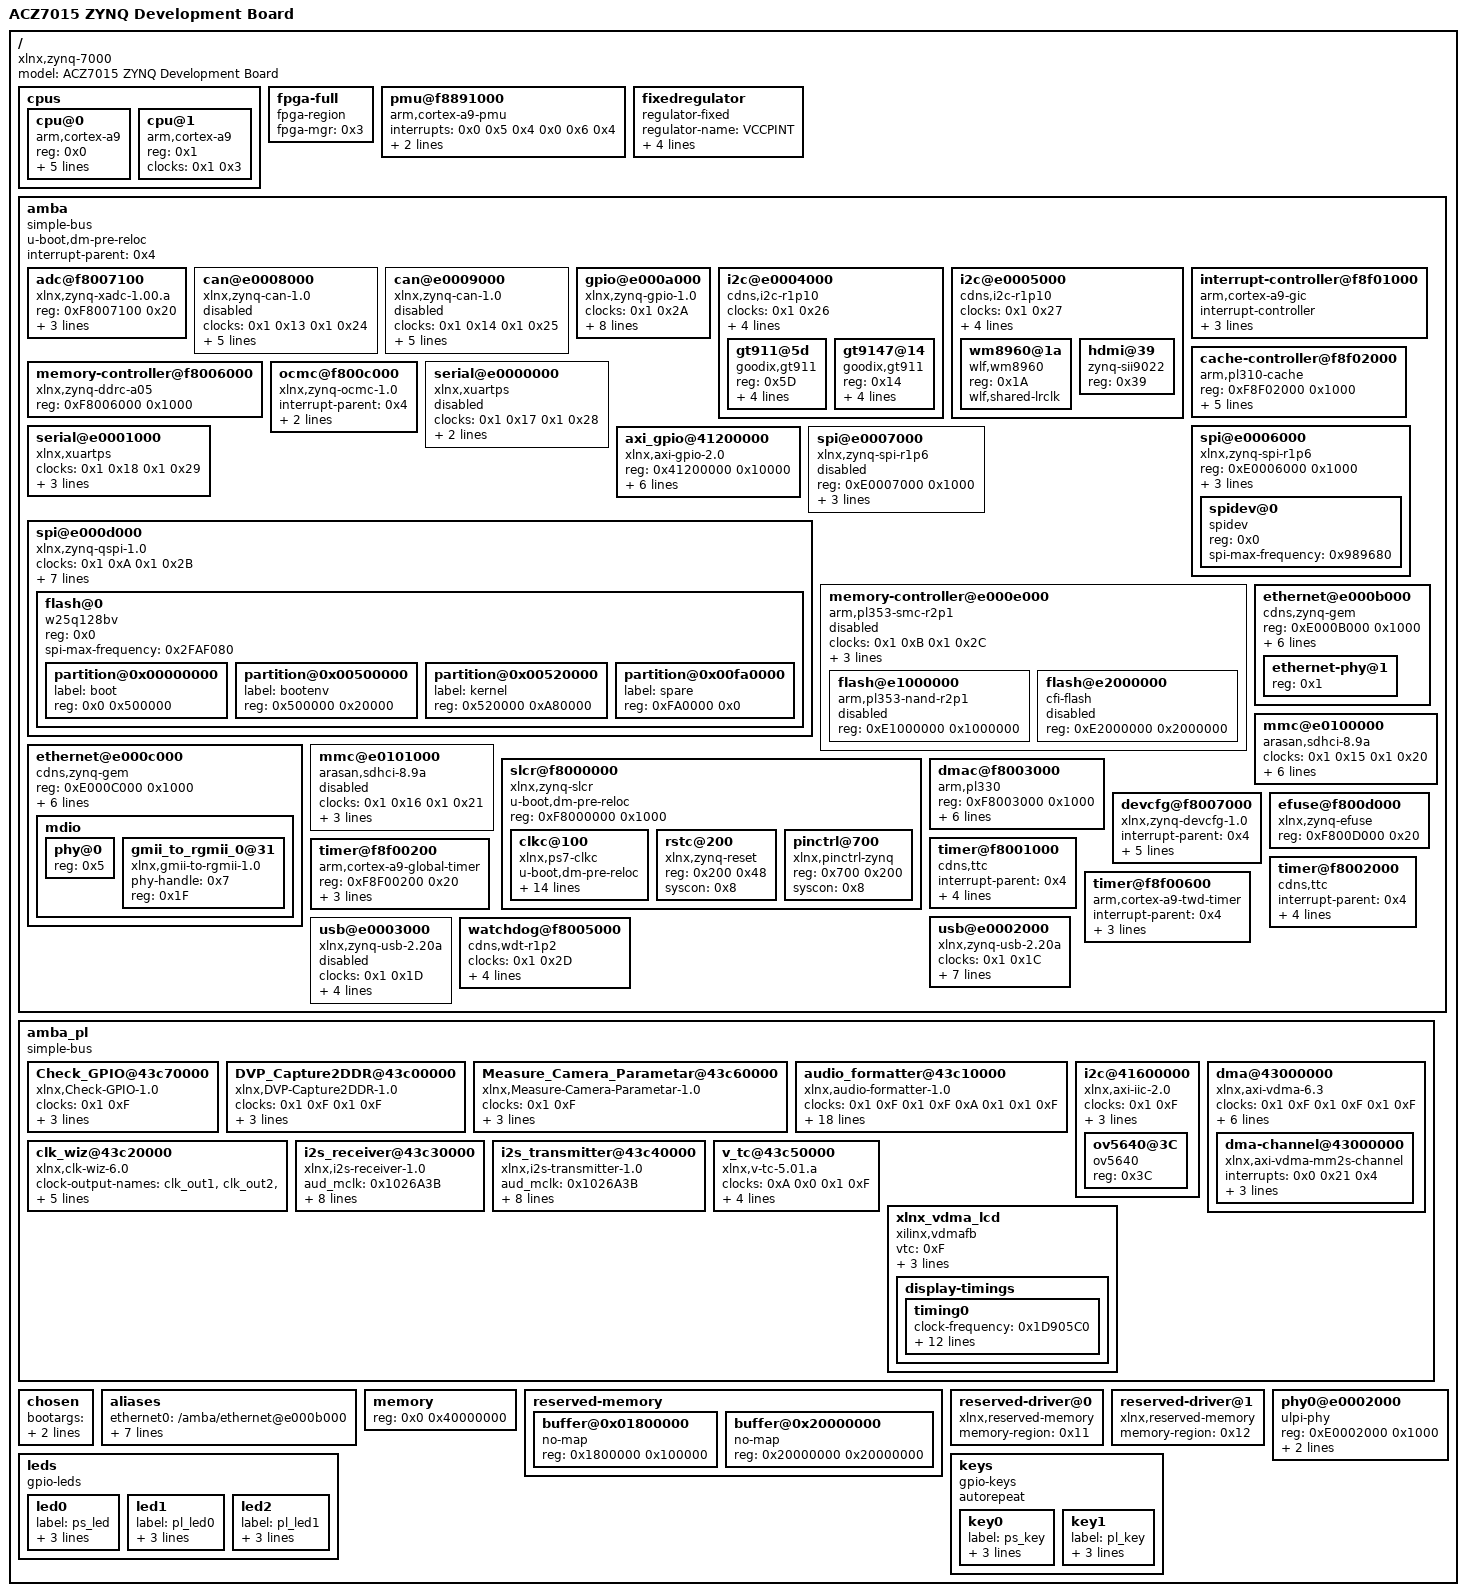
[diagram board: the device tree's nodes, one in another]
/dts-v1/;
// version: 17
// last_comp_version: 16
// boot_cpuid_phys: 0x0

/ {
    #address-cells = <0x1>;
    #size-cells = <0x1>;
    compatible = "xlnx,zynq-7000";
    model = "ACZ7015 ZYNQ Development Board";
    cpus {
        #address-cells = <0x1>;
        #size-cells = <0x0>;
        cpu@0 {
            compatible = "arm,cortex-a9";
            device_type = "cpu";
            reg = <0x0>;
            clocks = <0x1 0x3>;
            clock-latency = <0x3E8>;
            cpu0-supply = <0x2>;
            operating-points = <0xA2C2A 0xF4240 0x51615 0xF4240>;
        };
        cpu@1 {
            compatible = "arm,cortex-a9";
            device_type = "cpu";
            reg = <0x1>;
            clocks = <0x1 0x3>;
        };
    };
    fpga-full {
        compatible = "fpga-region";
        fpga-mgr = <0x3>;
        #address-cells = <0x1>;
        #size-cells = <0x1>;
        ranges;
    };
    pmu@f8891000 {
        compatible = "arm,cortex-a9-pmu";
        interrupts = <0x0 0x5 0x4 0x0 0x6 0x4>;
        interrupt-parent = <0x4>;
        reg = <0xF8891000 0x1000 0xF8893000 0x1000>;
    };
    fixedregulator {
        compatible = "regulator-fixed";
        regulator-name = "VCCPINT";
        regulator-min-microvolt = <0xF4240>;
        regulator-max-microvolt = <0xF4240>;
        regulator-boot-on;
        regulator-always-on;
        linux,phandle = <0x2>;
        phandle = <0x2>;
    };
    amba {
        u-boot,dm-pre-reloc;
        compatible = "simple-bus";
        #address-cells = <0x1>;
        #size-cells = <0x1>;
        interrupt-parent = <0x4>;
        ranges;
        adc@f8007100 {
            compatible = "xlnx,zynq-xadc-1.00.a";
            reg = <0xF8007100 0x20>;
            interrupts = <0x0 0x7 0x4>;
            interrupt-parent = <0x4>;
            clocks = <0x1 0xC>;
        };
        can@e0008000 {
            compatible = "xlnx,zynq-can-1.0";
            status = "disabled";
            clocks = <0x1 0x13 0x1 0x24>;
            clock-names = "can_clk", "pclk";
            reg = <0xE0008000 0x1000>;
            interrupts = <0x0 0x1C 0x4>;
            interrupt-parent = <0x4>;
            tx-fifo-depth = <0x40>;
            rx-fifo-depth = <0x40>;
        };
        can@e0009000 {
            compatible = "xlnx,zynq-can-1.0";
            status = "disabled";
            clocks = <0x1 0x14 0x1 0x25>;
            clock-names = "can_clk", "pclk";
            reg = <0xE0009000 0x1000>;
            interrupts = <0x0 0x33 0x4>;
            interrupt-parent = <0x4>;
            tx-fifo-depth = <0x40>;
            rx-fifo-depth = <0x40>;
        };
        gpio@e000a000 {
            compatible = "xlnx,zynq-gpio-1.0";
            #gpio-cells = <0x2>;
            clocks = <0x1 0x2A>;
            gpio-controller;
            interrupt-controller;
            #interrupt-cells = <0x2>;
            interrupt-parent = <0x4>;
            interrupts = <0x0 0x14 0x4>;
            reg = <0xE000A000 0x1000>;
            emio-gpio-width = <0x0>;
            gpio-mask-high = <0x0>;
            gpio-mask-low = <0x5600>;
            linux,phandle = <0x5>;
            phandle = <0x5>;
        };
        i2c@e0004000 {
            compatible = "cdns,i2c-r1p10";
            status = "okay";
            clocks = <0x1 0x26>;
            interrupt-parent = <0x4>;
            interrupts = <0x0 0x19 0x4>;
            reg = <0xE0004000 0x1000>;
            #address-cells = <0x1>;
            #size-cells = <0x0>;
            clock-frequency = <0x186A0>;
            gt911@5d {
                compatible = "goodix,gt911";
                status = "okay";
                reg = <0x5D>;
                interrupt-parent = <0x5>;
                interrupts = <0x0 0x0>;
                irq-gpios = <0x5 0x0 0x0>;
                reset-gpios = <0x5 0x38 0x1>;
            };
            gt9147@14 {
                compatible = "goodix,gt911";
                status = "okay";
                reg = <0x14>;
                interrupt-parent = <0x5>;
                interrupts = <0x0 0x0>;
                irq-gpios = <0x5 0x0 0x0>;
                reset-gpios = <0x5 0x38 0x1>;
            };
        };
        i2c@e0005000 {
            compatible = "cdns,i2c-r1p10";
            status = "okay";
            clocks = <0x1 0x27>;
            interrupt-parent = <0x4>;
            interrupts = <0x0 0x30 0x4>;
            reg = <0xE0005000 0x1000>;
            #address-cells = <0x1>;
            #size-cells = <0x0>;
            clock-frequency = <0x186A0>;
            wm8960@1a {
                compatible = "wlf,wm8960";
                reg = <0x1A>;
                #sound-dai-cells = <0x0>;
                wlf,shared-lrclk;
                linux,phandle = <0xD>;
                phandle = <0xD>;
            };
            hdmi@39 {
                compatible = "zynq-sii9022";
                reg = <0x39>;
            };
        };
        interrupt-controller@f8f01000 {
            compatible = "arm,cortex-a9-gic";
            #interrupt-cells = <0x3>;
            interrupt-controller;
            reg = <0xF8F01000 0x1000 0xF8F00100 0x100>;
            num_cpus = <0x2>;
            num_interrupts = <0x60>;
            linux,phandle = <0x4>;
            phandle = <0x4>;
        };
        cache-controller@f8f02000 {
            compatible = "arm,pl310-cache";
            reg = <0xF8F02000 0x1000>;
            interrupts = <0x0 0x2 0x4>;
            arm,data-latency = <0x3 0x2 0x2>;
            arm,tag-latency = <0x2 0x2 0x2>;
            cache-unified;
            cache-level = <0x2>;
        };
        memory-controller@f8006000 {
            compatible = "xlnx,zynq-ddrc-a05";
            reg = <0xF8006000 0x1000>;
        };
        ocmc@f800c000 {
            compatible = "xlnx,zynq-ocmc-1.0";
            interrupt-parent = <0x4>;
            interrupts = <0x0 0x3 0x4>;
            reg = <0xF800C000 0x1000>;
        };
        serial@e0000000 {
            compatible = "xlnx,xuartps", "cdns,uart-r1p8";
            status = "disabled";
            clocks = <0x1 0x17 0x1 0x28>;
            clock-names = "uart_clk", "pclk";
            reg = <0xE0000000 0x1000>;
            interrupts = <0x0 0x1B 0x4>;
        };
        serial@e0001000 {
            compatible = "xlnx,xuartps", "cdns,uart-r1p8";
            status = "okay";
            clocks = <0x1 0x18 0x1 0x29>;
            clock-names = "uart_clk", "pclk";
            reg = <0xE0001000 0x1000>;
            interrupts = <0x0 0x32 0x4>;
            device_type = "serial";
            port-number = <0x0>;
        };
        spi@e0006000 {
            compatible = "xlnx,zynq-spi-r1p6";
            reg = <0xE0006000 0x1000>;
            status = "okay";
            interrupt-parent = <0x4>;
            interrupts = <0x0 0x1A 0x4>;
            clocks = <0x1 0x19 0x1 0x22>;
            clock-names = "ref_clk", "pclk";
            #address-cells = <0x1>;
            #size-cells = <0x0>;
            spidev@0 {
                compatible = "spidev";
                reg = <0x0>;
                spi-max-frequency = <0x989680>;
                #address-cells = <0x1>;
                #size-cells = <0x0>;
            };
        };
        axi_gpio@41200000 {
            compatible = "xlnx,axi-gpio-2.0";
            reg = <0x41200000 0x10000>;
            xlnx,gpio-width = <0x8>;
            xlnx,all-inputs = <0x0>;
            xlnx,all-outputs = <0x0>;
            xlnx,dout-default = <0x0>;
            xlnx,tri-default = <0xFF>;
            #gpio-cells = <0x2>;
            gpio-controller;
        };
        spi@e0007000 {
            compatible = "xlnx,zynq-spi-r1p6";
            reg = <0xE0007000 0x1000>;
            status = "disabled";
            interrupt-parent = <0x4>;
            interrupts = <0x0 0x31 0x4>;
            clocks = <0x1 0x1A 0x1 0x23>;
            clock-names = "ref_clk", "pclk";
            #address-cells = <0x1>;
            #size-cells = <0x0>;
        };
        spi@e000d000 {
            clock-names = "ref_clk", "pclk";
            clocks = <0x1 0xA 0x1 0x2B>;
            compatible = "xlnx,zynq-qspi-1.0";
            status = "okay";
            interrupt-parent = <0x4>;
            interrupts = <0x0 0x13 0x4>;
            reg = <0xE000D000 0x1000>;
            #address-cells = <0x1>;
            #size-cells = <0x0>;
            is-dual = <0x0>;
            num-cs = <0x1>;
            spi-rx-bus-width = <0x4>;
            spi-tx-bus-width = <0x4>;
            flash@0 {
                compatible = "w25q128bv", "winbond,w25q128";
                reg = <0x0>;
                #address-cells = <0x1>;
                #size-cells = <0x1>;
                spi-max-frequency = <0x2FAF080>;
                partition@0x00000000 {
                    label = "boot";
                    reg = <0x0 0x500000>;
                };
                partition@0x00500000 {
                    label = "bootenv";
                    reg = <0x500000 0x20000>;
                };
                partition@0x00520000 {
                    label = "kernel";
                    reg = <0x520000 0xA80000>;
                };
                partition@0x00fa0000 {
                    label = "spare";
                    reg = <0xFA0000 0x0>;
                };
            };
        };
        memory-controller@e000e000 {
            #address-cells = <0x1>;
            #size-cells = <0x1>;
            status = "disabled";
            clock-names = "memclk", "aclk";
            clocks = <0x1 0xB 0x1 0x2C>;
            compatible = "arm,pl353-smc-r2p1";
            interrupt-parent = <0x4>;
            interrupts = <0x0 0x12 0x4>;
            ranges;
            reg = <0xE000E000 0x1000>;
            flash@e1000000 {
                status = "disabled";
                compatible = "arm,pl353-nand-r2p1";
                reg = <0xE1000000 0x1000000>;
                #address-cells = <0x1>;
                #size-cells = <0x1>;
            };
            flash@e2000000 {
                status = "disabled";
                compatible = "cfi-flash";
                reg = <0xE2000000 0x2000000>;
                #address-cells = <0x1>;
                #size-cells = <0x1>;
            };
        };
        ethernet@e000b000 {
            compatible = "cdns,zynq-gem", "cdns,gem";
            reg = <0xE000B000 0x1000>;
            status = "okay";
            interrupts = <0x0 0x16 0x4>;
            clocks = <0x1 0x1E 0x1 0x1E 0x1 0xD>;
            clock-names = "pclk", "hclk", "tx_clk";
            #address-cells = <0x1>;
            #size-cells = <0x0>;
            phy-mode = "rgmii-id";
            xlnx,ptp-enet-clock = <0x69F6BCB>;
            phy-handle = <0x6>;
            local-mac-address = [00 0A 35 00 1E 53];
            ethernet-phy@1 {
                reg = <0x1>;
                device_type = "ethernet-phy";
                linux,phandle = <0x6>;
                phandle = <0x6>;
            };
        };
        ethernet@e000c000 {
            compatible = "cdns,zynq-gem", "cdns,gem";
            reg = <0xE000C000 0x1000>;
            status = "okay";
            interrupts = <0x0 0x2D 0x4>;
            clocks = <0x1 0x1F 0x1 0x1F 0x1 0xE>;
            clock-names = "pclk", "hclk", "tx_clk";
            #address-cells = <0x1>;
            #size-cells = <0x0>;
            phy-handle = <0x7>;
            phy-mode = "gmii";
            xlnx,ptp-enet-clock = <0x69F6BCB>;
            local-mac-address = [00 0A 35 00 11 55];
            mdio {
                #address-cells = <0x1>;
                #size-cells = <0x0>;
                phy@0 {
                    device_type = "ethernet-phy";
                    reg = <0x5>;
                    linux,phandle = <0x7>;
                    phandle = <0x7>;
                };
                gmii_to_rgmii_0@31 {
                    compatible = "xlnx,gmii-to-rgmii-1.0";
                    phy-handle = <0x7>;
                    reg = <0x1F>;
                };
            };
        };
        mmc@e0100000 {
            compatible = "arasan,sdhci-8.9a";
            status = "okay";
            clock-names = "clk_xin", "clk_ahb";
            clocks = <0x1 0x15 0x1 0x20>;
            interrupt-parent = <0x4>;
            interrupts = <0x0 0x18 0x4>;
            reg = <0xE0100000 0x1000>;
            xlnx,has-cd = <0x0>;
            xlnx,has-power = <0x0>;
            xlnx,has-wp = <0x0>;
        };
        mmc@e0101000 {
            compatible = "arasan,sdhci-8.9a";
            status = "disabled";
            clock-names = "clk_xin", "clk_ahb";
            clocks = <0x1 0x16 0x1 0x21>;
            interrupt-parent = <0x4>;
            interrupts = <0x0 0x2F 0x4>;
            reg = <0xE0101000 0x1000>;
        };
        slcr@f8000000 {
            u-boot,dm-pre-reloc;
            #address-cells = <0x1>;
            #size-cells = <0x1>;
            compatible = "xlnx,zynq-slcr", "syscon", "simple-mfd";
            reg = <0xF8000000 0x1000>;
            ranges;
            linux,phandle = <0x8>;
            phandle = <0x8>;
            clkc@100 {
                u-boot,dm-pre-reloc;
                #clock-cells = <0x1>;
                compatible = "xlnx,ps7-clkc";
                fclk-enable = <0x7>;
                clock-output-names = "armpll", "ddrpll", "iopll", "cpu_6or4x", "cpu_3or2x", "cpu_2x", "cpu_1x", "ddr2x", "ddr3x", "dci", "lqspi", "smc", "pcap", "gem0", "gem1", "fclk0", "fclk1", "fclk2", "fclk3", "can0", "can1", "sdio0", "sdio1", "uart0", "uart1", "spi0", "spi1", "dma", "usb0_aper", "usb1_aper", "gem0_aper", "gem1_aper", "sdio0_aper", "sdio1_aper", "spi0_aper", "spi1_aper", "can0_aper", "can1_aper", "i2c0_aper", "i2c1_aper", "uart0_aper", "uart1_aper", "gpio_aper", "lqspi_aper", "smc_aper", "swdt", "dbg_trc", "dbg_apb";
                reg = <0x100 0x100>;
                ps-clk-frequency = <0x1FCA055>;
                linux,phandle = <0x1>;
                phandle = <0x1>;
            };
            rstc@200 {
                compatible = "xlnx,zynq-reset";
                reg = <0x200 0x48>;
                #reset-cells = <0x1>;
                syscon = <0x8>;
            };
            pinctrl@700 {
                compatible = "xlnx,pinctrl-zynq";
                reg = <0x700 0x200>;
                syscon = <0x8>;
            };
        };
        dmac@f8003000 {
            compatible = "arm,pl330", "arm,primecell";
            reg = <0xF8003000 0x1000>;
            interrupt-parent = <0x4>;
            interrupt-names = "abort", "dma0", "dma1", "dma2", "dma3", "dma4", "dma5", "dma6", "dma7";
            interrupts = <0x0 0xD 0x4 0x0 0xE 0x4 0x0 0xF 0x4 0x0 0x10 0x4 0x0 0x11 0x4 0x0 0x28 0x4 0x0 0x29 0x4 0x0 0x2A 0x4 0x0 0x2B 0x4>;
            #dma-cells = <0x1>;
            #dma-channels = <0x8>;
            #dma-requests = <0x4>;
            clocks = <0x1 0x1B>;
            clock-names = "apb_pclk";
        };
        devcfg@f8007000 {
            compatible = "xlnx,zynq-devcfg-1.0";
            interrupt-parent = <0x4>;
            interrupts = <0x0 0x8 0x4>;
            reg = <0xF8007000 0x100>;
            clocks = <0x1 0xC 0x1 0xF 0x1 0x10 0x1 0x11 0x1 0x12>;
            clock-names = "ref_clk", "fclk0", "fclk1", "fclk2", "fclk3";
            syscon = <0x8>;
            linux,phandle = <0x3>;
            phandle = <0x3>;
        };
        efuse@f800d000 {
            compatible = "xlnx,zynq-efuse";
            reg = <0xF800D000 0x20>;
        };
        timer@f8f00200 {
            compatible = "arm,cortex-a9-global-timer";
            reg = <0xF8F00200 0x20>;
            interrupts = <0x1 0xB 0x301>;
            interrupt-parent = <0x4>;
            clocks = <0x1 0x4>;
        };
        timer@f8001000 {
            interrupt-parent = <0x4>;
            interrupts = <0x0 0xA 0x4 0x0 0xB 0x4 0x0 0xC 0x4>;
            compatible = "cdns,ttc";
            clocks = <0x1 0x6>;
            reg = <0xF8001000 0x1000>;
        };
        timer@f8002000 {
            interrupt-parent = <0x4>;
            interrupts = <0x0 0x25 0x4 0x0 0x26 0x4 0x0 0x27 0x4>;
            compatible = "cdns,ttc";
            clocks = <0x1 0x6>;
            reg = <0xF8002000 0x1000>;
        };
        timer@f8f00600 {
            interrupt-parent = <0x4>;
            interrupts = <0x1 0xD 0x301>;
            compatible = "arm,cortex-a9-twd-timer";
            reg = <0xF8F00600 0x20>;
            clocks = <0x1 0x4>;
        };
        usb@e0002000 {
            compatible = "xlnx,zynq-usb-2.20a", "chipidea,usb2";
            status = "okay";
            clocks = <0x1 0x1C>;
            interrupt-parent = <0x4>;
            interrupts = <0x0 0x15 0x4>;
            reg = <0xE0002000 0x1000>;
            phy_type = "ulpi";
            usb-reset = <0x5 0x2E 0x0>;
            dr_mode = "host";
            usb-phy = <0x9>;
        };
        usb@e0003000 {
            compatible = "xlnx,zynq-usb-2.20a", "chipidea,usb2";
            status = "disabled";
            clocks = <0x1 0x1D>;
            interrupt-parent = <0x4>;
            interrupts = <0x0 0x2C 0x4>;
            reg = <0xE0003000 0x1000>;
            phy_type = "ulpi";
        };
        watchdog@f8005000 {
            clocks = <0x1 0x2D>;
            compatible = "cdns,wdt-r1p2";
            interrupt-parent = <0x4>;
            interrupts = <0x0 0x9 0x1>;
            reg = <0xF8005000 0x1000>;
            timeout-sec = <0xA>;
        };
    };
    amba_pl {
        #address-cells = <0x1>;
        #size-cells = <0x1>;
        compatible = "simple-bus";
        ranges;
        Check_GPIO@43c70000 {
            clock-names = "s00_axi_aclk";
            clocks = <0x1 0xF>;
            compatible = "xlnx,Check-GPIO-1.0";
            reg = <0x43C70000 0x10000>;
            xlnx,s00-axi-addr-width = <0x4>;
            xlnx,s00-axi-data-width = <0x20>;
        };
        DVP_Capture2DDR@43c00000 {
            clock-names = "M_AXI_ACLK", "s00_axi_aclk";
            clocks = <0x1 0xF 0x1 0xF>;
            compatible = "xlnx,DVP-Capture2DDR-1.0";
            reg = <0x43C00000 0x10000>;
            xlnx,s00-axi-addr-width = <0x4>;
            xlnx,s00-axi-data-width = <0x20>;
        };
        Measure_Camera_Parametar@43c60000 {
            clock-names = "s00_axi_aclk";
            clocks = <0x1 0xF>;
            compatible = "xlnx,Measure-Camera-Parametar-1.0";
            reg = <0x43C60000 0x10000>;
            xlnx,s00-axi-addr-width = <0x4>;
            xlnx,s00-axi-data-width = <0x20>;
        };
        audio_formatter@43c10000 {
            clock-names = "s_axi_lite_aclk", "m_axis_mm2s_aclk", "aud_mclk", "s_axis_s2mm_aclk";
            clocks = <0x1 0xF 0x1 0xF 0xA 0x1 0x1 0xF>;
            compatible = "xlnx,audio-formatter-1.0", "xlnx,audio-formatter-1.0";
            interrupt-names = "irq_mm2s", "irq_s2mm";
            interrupt-parent = <0x4>;
            interrupts = <0x0 0x1E 0x4 0x0 0x1F 0x4>;
            reg = <0x43C10000 0x10000>;
            xlnx,include-mm2s = <0x1>;
            xlnx,include-s2mm = <0x1>;
            xlnx,max-num-channels-mm2s = <0x2>;
            xlnx,max-num-channels-s2mm = <0x2>;
            xlnx,mm2s-addr-width = <0x40>;
            xlnx,mm2s-async-clock = <0x1>;
            xlnx,mm2s-dataformat = <0x3>;
            xlnx,packing-mode-mm2s = <0x0>;
            xlnx,packing-mode-s2mm = <0x0>;
            xlnx,s2mm-addr-width = <0x40>;
            xlnx,s2mm-async-clock = <0x1>;
            xlnx,s2mm-dataformat = <0x1>;
            xlnx,tx = <0xB>;
            xlnx,rx = <0xC>;
            audio-codec = <0xD>;
            linux,phandle = <0xE>;
            phandle = <0xE>;
        };
        i2c@41600000 {
            #address-cells = <0x1>;
            #size-cells = <0x0>;
            clock-names = "s_axi_aclk";
            clocks = <0x1 0xF>;
            compatible = "xlnx,axi-iic-2.0", "xlnx,xps-iic-2.00.a";
            interrupt-names = "iic2intc_irpt";
            interrupt-parent = <0x4>;
            interrupts = <0x0 0x23 0x4>;
            reg = <0x41600000 0x10000>;
            ov5640@3C {
                compatible = "ov5640";
                reg = <0x3C>;
            };
        };
        dma@43000000 {
            #dma-cells = <0x1>;
            clock-names = "s_axi_lite_aclk", "m_axi_mm2s_aclk", "m_axis_mm2s_aclk";
            clocks = <0x1 0xF 0x1 0xF 0x1 0xF>;
            compatible = "xlnx,axi-vdma-6.3", "xlnx,axi-vdma-1.00.a";
            interrupt-names = "mm2s_introut";
            interrupt-parent = <0x4>;
            interrupts = <0x0 0x21 0x4>;
            reg = <0x43000000 0x10000>;
            xlnx,addrwidth = <0x20>;
            xlnx,flush-fsync = <0x1>;
            xlnx,num-fstores = <0x1>;
            linux,phandle = <0x10>;
            phandle = <0x10>;
            dma-channel@43000000 {
                compatible = "xlnx,axi-vdma-mm2s-channel";
                interrupts = <0x0 0x21 0x4>;
                xlnx,datawidth = <0x10>;
                xlnx,device-id = <0x0>;
                xlnx,genlock-mode;
            };
        };
        clk_wiz@43c20000 {
            #clock-cells = <0x1>;
            clock-names = "s_axi_aclk", "clk_in1";
            clock-output-names = "clk_out1", "clk_out2", "clk_out3", "clk_out4", "clk_out5", "clk_out6", "clk_out7";
            clocks = <0x1 0xF 0x1 0xF>;
            compatible = "xlnx,clk-wiz-6.0", "xlnx,clocking-wizard";
            reg = <0x43C20000 0x10000>;
            speed-grade = <0x1>;
            linux,phandle = <0xA>;
            phandle = <0xA>;
        };
        i2s_receiver@43c30000 {
            aud_mclk = <0x1026A3B>;
            clock-names = "s_axi_ctrl_aclk", "aud_mclk", "m_axis_aud_aclk";
            clocks = <0x1 0xF 0xA 0x1 0x1 0xF>;
            compatible = "xlnx,i2s-receiver-1.0", "xlnx,i2s-receiver-1.0";
            interrupt-names = "irq";
            interrupt-parent = <0x4>;
            interrupts = <0x0 0x1D 0x4>;
            reg = <0x43C30000 0x10000>;
            xlnx,depth = <0x80>;
            xlnx,dwidth = <0x18>;
            xlnx,num-channels = <0x1>;
            xlnx,snd-pcm = <0xE>;
            linux,phandle = <0xC>;
            phandle = <0xC>;
        };
        i2s_transmitter@43c40000 {
            aud_mclk = <0x1026A3B>;
            clock-names = "s_axi_ctrl_aclk", "aud_mclk", "s_axis_aud_aclk";
            clocks = <0x1 0xF 0xA 0x1 0x1 0xF>;
            compatible = "xlnx,i2s-transmitter-1.0", "xlnx,i2s-transmitter-1.0";
            interrupt-names = "irq";
            interrupt-parent = <0x4>;
            interrupts = <0x0 0x20 0x4>;
            reg = <0x43C40000 0x10000>;
            xlnx,depth = <0x80>;
            xlnx,dwidth = <0x18>;
            xlnx,num-channels = <0x1>;
            xlnx,snd-pcm = <0xE>;
            linux,phandle = <0xB>;
            phandle = <0xB>;
        };
        v_tc@43c50000 {
            clock-names = "clk", "s_axi_aclk";
            clocks = <0xA 0x0 0x1 0xF>;
            compatible = "xlnx,v-tc-5.01.a";
            interrupt-names = "irq";
            interrupt-parent = <0x4>;
            interrupts = <0x0 0x22 0x4>;
            reg = <0x43C50000 0x10000>;
            xlnx,generator;
            linux,phandle = <0xF>;
            phandle = <0xF>;
        };
        xlnx_vdma_lcd {
            compatible = "xilinx,vdmafb";
            vtc = <0xF>;
            clocks = <0xA 0x0>;
            clock-names = "lcd_pclk";
            dmas = <0x10 0x0>;
            dma-names = "lcd_vdma";
            pixel-format = "RGB565";
            display-timings {
                timing0 {
                    clock-frequency = <0x1D905C0>;
                    hactive = <0x320>;
                    vactive = <0x1E0>;
                    hback-porch = <0x58>;
                    hfront-porch = <0x28>;
                    hsync-len = <0x30>;
                    vback-porch = <0x20>;
                    vfront-porch = <0xD>;
                    vsync-len = <0x3>;
                    hsync-active = <0x0>;
                    vsync-active = <0x0>;
                    de-active = <0x1>;
                    pixelclk-active = <0x0>;
                };
            };
        };
    };
    chosen {
        bootargs = "console=ttyPS0,115200 earlyprintk root=/dev/mmcblk0p2 rw rootwait";
        stdout-path = "serial0:115200n8";
    };
    aliases {
        ethernet0 = "/amba/ethernet@e000b000";
        ethernet1 = "/amba/ethernet@e000c000";
        i2c0 = "/amba_pl/i2c@41600000";
        i2c1 = "/amba/i2c@e0004000";
        i2c2 = "/amba/i2c@e0005000";
        serial0 = "/amba/serial@e0001000";
        spi0 = "/amba/spi@e0006000";
        spi1 = "/amba/spi@e000d000";
    };
    memory {
        device_type = "memory";
        reg = <0x0 0x40000000>;
    };
    reserved-memory {
        #address-cells = <0x1>;
        #size-cells = <0x1>;
        ranges;
        buffer@0x01800000 {
            no-map;
            reg = <0x1800000 0x100000>;
            linux,phandle = <0x11>;
            phandle = <0x11>;
        };
        buffer@0x20000000 {
            no-map;
            reg = <0x20000000 0x20000000>;
            linux,phandle = <0x12>;
            phandle = <0x12>;
        };
    };
    reserved-driver@0 {
        compatible = "xlnx,reserved-memory";
        memory-region = <0x11>;
    };
    reserved-driver@1 {
        compatible = "xlnx,reserved-memory";
        memory-region = <0x12>;
    };
    leds {
        compatible = "gpio-leds";
        led0 {
            label = "ps_led";
            gpios = <0x5 0x7 0x0>;
            linux,default-trigger = "heartbeat";
            default-state = "on";
        };
        led1 {
            label = "pl_led0";
            gpios = <0x5 0x36 0x0>;
            linux,default-trigger = "heartbeat";
            default-state = "on";
        };
        led2 {
            label = "pl_led1";
            gpios = <0x5 0x3A 0x0>;
            linux,default-trigger = "heartbeat";
            default-state = "on";
        };
    };
    keys {
        compatible = "gpio-keys";
        autorepeat;
        key0 {
            label = "ps_key";
            linux,code = <0x67>;
            gpios = <0x5 0x2F 0x1>;
            debounce-interval = <0xF>;
        };
        key1 {
            label = "pl_key";
            linux,code = <0x1C>;
            gpios = <0x5 0x37 0x1>;
            debounce-interval = <0xF>;
        };
    };
    phy0@e0002000 {
        compatible = "ulpi-phy";
        #phy-cells = <0x0>;
        reg = <0xE0002000 0x1000>;
        view-port = <0x170>;
        drv-vbus;
        linux,phandle = <0x9>;
        phandle = <0x9>;
    };
};
